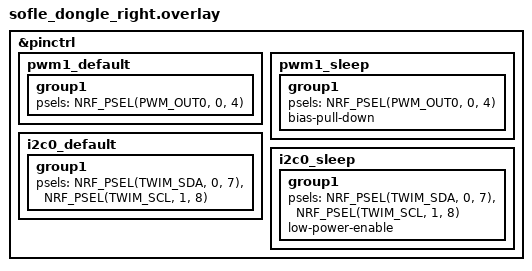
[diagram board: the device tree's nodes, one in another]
/*
 * 右半「模块插座」的引脚定义（设备树那一半）。
 *
 * 右座目前只有小红点的资料（MODULAR_POINTER_ANALYSIS.md §4.2）：
 *
 *   小红点 MOTION P0.14  （在 .conf 里，见 config/sofle_dongle_right.conf）
 *   小红点 I2C SDA P0.07
 *   小红点 I2C SCL P1.08
 *   模块主 LED     P0.04
 *
 * 右座的轨迹球/触摸板引脚源码里没有，所以那边保持「未定义」，
 * 真去编 side=right + ball/pad 的组合会在 C 里 #error 拒绝（见各驱动开头）。
 *
 * 注意：本文件同时补上了 sofle_dongle_right.dts 里 &pwm1 引用的
 * pwm1_default/pwm1_sleep —— 原先那两个节点在右板 dts 里是悬空的。
 */

&pinctrl {
    /* 模块主 LED（小红点那侧没有第二颗 LED，所以只有 pwm1） */
    pwm1_default: pwm1_default {
        group1 {
            psels = <NRF_PSEL(PWM_OUT0, 0, 4)>;
        };
    };

    pwm1_sleep: pwm1_sleep {
        group1 {
            psels = <NRF_PSEL(PWM_OUT0, 0, 4)>;
            bias-pull-down;
        };
    };

    /* 模块插座上的 I2C，小红点用 */
    i2c0_default: i2c0_default {
        group1 {
            psels = <NRF_PSEL(TWIM_SDA, 0, 7)>,
                    <NRF_PSEL(TWIM_SCL, 1, 8)>;
        };
    };

    i2c0_sleep: i2c0_sleep {
        group1 {
            psels = <NRF_PSEL(TWIM_SDA, 0, 7)>,
                    <NRF_PSEL(TWIM_SCL, 1, 8)>;
            low-power-enable;
        };
    };
};
